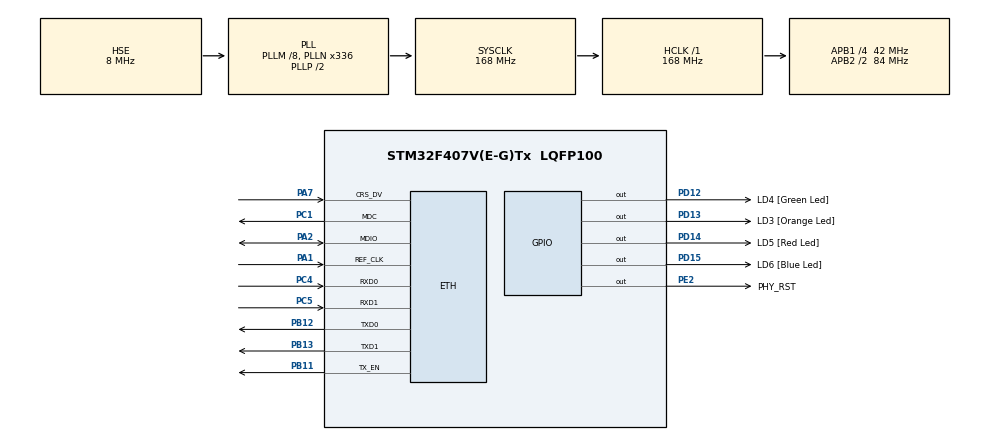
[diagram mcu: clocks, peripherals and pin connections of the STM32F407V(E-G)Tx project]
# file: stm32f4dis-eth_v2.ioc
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ETH.MACAddr=00\:80\:E1\:00\:19\:18
ETH.MediaInterface=ETH_MEDIA_INTERFACE_RMII
FREERTOS.Tasks01=defaultTask,24,512,StartDefaultTask,Default,NULL,Dynamic,NULL,NULL
LWIP.LWIP_DHCP=1
LWIP.LWIP_HTTPD=1
LWIP.Version=v2.1.2_Cube
Mcu.Family=STM32F4
Mcu.Name=STM32F407V(E-G)Tx
Mcu.Package=LQFP100
NVIC.ETH_IRQn=true\:5\:0\:false\:false\:true\:true\:false\:true
NVIC.PriorityGroup=NVIC_PRIORITYGROUP_4
NVIC.TIM1_UP_TIM10_IRQn=true\:0\:0\:false\:false\:true\:false\:false\:true
NVIC.TimeBase=TIM1_UP_TIM10_IRQn
NVIC.TimeBaseIP=TIM1
PA1.Mode=RMII
PA1.Signal=ETH_REF_CLK
PA13.GPIO_Label=SWDIO
PA13.Mode=Serial_Wire
PA13.Signal=SYS_JTMS-SWDIO
PA14.GPIO_Label=SWCLK
PA14.Mode=Serial_Wire
PA14.Signal=SYS_JTCK-SWCLK
PA2.Mode=RMII
PA2.Signal=ETH_MDIO
PA7.Mode=RMII
PA7.Signal=ETH_CRS_DV
PB11.Mode=RMII
PB11.Signal=ETH_TX_EN
PB12.Mode=RMII
PB12.Signal=ETH_TXD0
PB13.Mode=RMII
PB13.Signal=ETH_TXD1
PC1.Mode=RMII
PC1.Signal=ETH_MDC
PC14-OSC32_IN.GPIO_Label=PC14-OSC32_IN
PC14-OSC32_IN.Mode=LSE-External-Oscillator
PC14-OSC32_IN.Signal=RCC_OSC32_IN
PC15-OSC32_OUT.GPIO_Label=PC15-OSC32_OUT
PC15-OSC32_OUT.Mode=LSE-External-Oscillator
PC15-OSC32_OUT.Signal=RCC_OSC32_OUT
PC4.Mode=RMII
PC4.Signal=ETH_RXD0
PC5.Mode=RMII
PC5.Signal=ETH_RXD1
PD12.GPIO_Label=LD4 [Green Led]
PD12.GPIO_PuPd=GPIO_NOPULL
PD12.GPIO_Speed=GPIO_SPEED_FREQ_LOW
PD12.Signal=GPIO_Output
PD13.GPIO_Label=LD3 [Orange Led]
PD13.GPIO_PuPd=GPIO_NOPULL
PD13.GPIO_Speed=GPIO_SPEED_FREQ_LOW
PD13.Signal=GPIO_Output
PD14.GPIO_Label=LD5 [Red Led]
PD14.GPIO_PuPd=GPIO_NOPULL
PD14.GPIO_Speed=GPIO_SPEED_FREQ_LOW
PD14.Signal=GPIO_Output
PD15.GPIO_Label=LD6 [Blue Led]
PD15.GPIO_PuPd=GPIO_NOPULL
PD15.GPIO_Speed=GPIO_SPEED_FREQ_LOW
PD15.Signal=GPIO_Output
PE2.GPIO_Label=PHY_RST
PE2.GPIO_PuPd=GPIO_NOPULL
PE2.GPIO_Speed=GPIO_SPEED_FREQ_LOW
PE2.Signal=GPIO_Output
PH0-OSC_IN.GPIO_Label=PH0-OSC_IN
PH0-OSC_IN.Mode=HSE-External-Oscillator
PH0-OSC_IN.Signal=RCC_OSC_IN
PH1-OSC_OUT.GPIO_Label=PH1-OSC_OUT
PH1-OSC_OUT.Mode=HSE-External-Oscillator
PH1-OSC_OUT.Signal=RCC_OSC_OUT
ProjectManager.HeapSize=0x200
ProjectManager.StackSize=0x400
ProjectManager.TargetToolchain=MDK-ARM V5.27
RCC.48MHZClocksFreq_Value=48000000
RCC.AHBFreq_Value=168000000
RCC.APB1CLKDivider=RCC_HCLK_DIV4
RCC.APB1Freq_Value=42000000
RCC.APB1TimFreq_Value=84000000
RCC.APB2CLKDivider=RCC_HCLK_DIV2
RCC.APB2Freq_Value=84000000
RCC.APB2TimFreq_Value=168000000
RCC.CortexFreq_Value=168000000
RCC.HCLKFreq_Value=168000000
RCC.HSE_VALUE=8000000
RCC.HSI_VALUE=16000000
RCC.PLLM=8
RCC.PLLN=336
RCC.PLLQ=7
RCC.PLLSourceVirtual=RCC_PLLSOURCE_HSE
RCC.SYSCLKFreq_VALUE=168000000
RCC.SYSCLKSource=RCC_SYSCLKSOURCE_PLLCLK
RCC.VCOOutputFreq_Value=336000000
VP_FREERTOS_VS_CMSIS_V2.Mode=CMSIS_V2
VP_LWIP_VS_Enabled.Mode=Enabled
VP_SYS_VS_tim1.Mode=TIM1
board=STM32F407G-DISC1

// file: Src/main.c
/* USER CODE BEGIN Header */
/**
  ******************************************************************************
  * @file           : main.c
  * @brief          : Main program body
  ******************************************************************************
  * @attention
  *
  * <h2><center>&copy; Copyright (c) 2020 STMicroelectronics.
  * All rights reserved.</center></h2>
  *
  * This software component is licensed by ST under Ultimate Liberty license
  * SLA0044, the "License"; You may not use this file except in compliance with
  * the License. You may obtain a copy of the License at:
  *                             www.st.com/SLA0044
  *
  ******************************************************************************
  */
/* USER CODE END Header */

#include "main.h"
#include "cmsis_os.h"
#include "lwip.h"

/* Definitions for defaultTask */
osThreadId_t defaultTaskHandle;
const osThreadAttr_t defaultTask_attributes = {
  .name = "defaultTask",
  .priority = (osPriority_t) osPriorityNormal,
  .stack_size = 512 * 4
};

void SystemClock_Config(void);
static void MX_GPIO_Init(void);
void StartDefaultTask(void *argument);

int main(void)
{

  /* MCU Configuration--------------------------------------------------------*/

  /* Reset of all peripherals, Initializes the Flash interface and the Systick. */
  HAL_Init();

  /* Configure the system clock */
  SystemClock_Config();

  /* Initialize all configured peripherals */
  MX_GPIO_Init();

  /* Init scheduler */
  osKernelInitialize();

  /* Create the thread(s) */
  /* creation of defaultTask */
  defaultTaskHandle = osThreadNew(StartDefaultTask, NULL, &defaultTask_attributes);

  /* Start scheduler */
  osKernelStart();
  /* We should never get here as control is now taken by the scheduler */
  /* Infinite loop */
  while (1)
  {

  }
}

void SystemClock_Config(void)
{
  RCC_OscInitTypeDef RCC_OscInitStruct = {0};
  RCC_ClkInitTypeDef RCC_ClkInitStruct = {0};

  /** Configure the main internal regulator output voltage
  */
  __HAL_RCC_PWR_CLK_ENABLE();
  __HAL_PWR_VOLTAGESCALING_CONFIG(PWR_REGULATOR_VOLTAGE_SCALE1);
  /** Initializes the CPU, AHB and APB busses clocks
  */
  RCC_OscInitStruct.OscillatorType = RCC_OSCILLATORTYPE_HSE;
  RCC_OscInitStruct.HSEState = RCC_HSE_ON;
  RCC_OscInitStruct.PLL.PLLState = RCC_PLL_ON;
  RCC_OscInitStruct.PLL.PLLSource = RCC_PLLSOURCE_HSE;
  RCC_OscInitStruct.PLL.PLLM = 8;
  RCC_OscInitStruct.PLL.PLLN = 336;
  RCC_OscInitStruct.PLL.PLLP = RCC_PLLP_DIV2;
  RCC_OscInitStruct.PLL.PLLQ = 7;
  if (HAL_RCC_OscConfig(&RCC_OscInitStruct) != HAL_OK)
  {
    Error_Handler();
  }
  /** Initializes the CPU, AHB and APB busses clocks
  */
  RCC_ClkInitStruct.ClockType = RCC_CLOCKTYPE_HCLK|RCC_CLOCKTYPE_SYSCLK
                              |RCC_CLOCKTYPE_PCLK1|RCC_CLOCKTYPE_PCLK2;
  RCC_ClkInitStruct.SYSCLKSource = RCC_SYSCLKSOURCE_PLLCLK;
  RCC_ClkInitStruct.AHBCLKDivider = RCC_SYSCLK_DIV1;
  RCC_ClkInitStruct.APB1CLKDivider = RCC_HCLK_DIV4;
  RCC_ClkInitStruct.APB2CLKDivider = RCC_HCLK_DIV2;

  if (HAL_RCC_ClockConfig(&RCC_ClkInitStruct, FLASH_LATENCY_5) != HAL_OK)
  {
    Error_Handler();
  }
}

static void MX_GPIO_Init(void)
{
  GPIO_InitTypeDef GPIO_InitStruct = {0};

  /* GPIO Ports Clock Enable */
  __HAL_RCC_GPIOE_CLK_ENABLE();
  __HAL_RCC_GPIOC_CLK_ENABLE();
  __HAL_RCC_GPIOH_CLK_ENABLE();
  __HAL_RCC_GPIOA_CLK_ENABLE();
  __HAL_RCC_GPIOB_CLK_ENABLE();
  __HAL_RCC_GPIOD_CLK_ENABLE();

  /*Configure GPIO pin Output Level */
  HAL_GPIO_WritePin(PHY_RST_GPIO_Port, PHY_RST_Pin, GPIO_PIN_RESET);

  /*Configure GPIO pin Output Level */
  HAL_GPIO_WritePin(GPIOD, LD4_Pin|LD3_Pin|LD5_Pin|LD6_Pin, GPIO_PIN_RESET);

  /*Configure GPIO pin : PHY_RST_Pin */
  GPIO_InitStruct.Pin = PHY_RST_Pin;
  GPIO_InitStruct.Mode = GPIO_MODE_OUTPUT_PP;
  GPIO_InitStruct.Pull = GPIO_NOPULL;
  GPIO_InitStruct.Speed = GPIO_SPEED_FREQ_LOW;
  HAL_GPIO_Init(PHY_RST_GPIO_Port, &GPIO_InitStruct);

  /*Configure GPIO pins : LD4_Pin LD3_Pin LD5_Pin LD6_Pin */
  GPIO_InitStruct.Pin = LD4_Pin|LD3_Pin|LD5_Pin|LD6_Pin;
  GPIO_InitStruct.Mode = GPIO_MODE_OUTPUT_PP;
  GPIO_InitStruct.Pull = GPIO_NOPULL;
  GPIO_InitStruct.Speed = GPIO_SPEED_FREQ_LOW;
  HAL_GPIO_Init(GPIOD, &GPIO_InitStruct);

}

void StartDefaultTask(void *argument)
{
  /* init code for LWIP */
  MX_LWIP_Init();
  /* USER CODE BEGIN 5 */
	  HAL_GPIO_WritePin(GPIOD, LD4_Pin|LD3_Pin|LD5_Pin|LD6_Pin, GPIO_PIN_SET);

  /* Infinite loop */
  for(;;)
  {
    osDelay(1);
  }
  /* USER CODE END 5 */
}

 /**
  * @brief  Period elapsed callback in non blocking mode
  * @note   This function is called  when TIM1 interrupt took place, inside
  * HAL_TIM_IRQHandler(). It makes a direct call to HAL_IncTick() to increment
  * a global variable "uwTick" used as application time base.
  * @param  htim : TIM handle
  * @retval None
  */
void HAL_TIM_PeriodElapsedCallback(TIM_HandleTypeDef *htim)
{
  if (htim->Instance == TIM1) {
    HAL_IncTick();
  }
}

void Error_Handler(void)
{
}

/************************ (C) COPYRIGHT STMicroelectronics *****END OF FILE****/
